# WOF register map
Registers are 32-bit, write-only, no defined reset value unless marked. A register's access mark holds for its fields unless they carry their own. Offsets are from the block's base; lines under a group give offsets from that group; [hi:lo] are bit positions; {n}, {i} and the like mark numbered series; 'fields as' and 'values as' point back to an identical list; <NAME> marks a mode.

## Memory map
0x40000000 P

## P
Base 0x40000000
0x00 WO
  [7:0] F ro
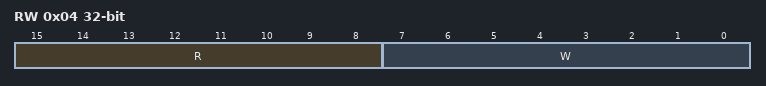
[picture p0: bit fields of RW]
0x04 RW rw
  [15:8] R, [7:0] W wo
